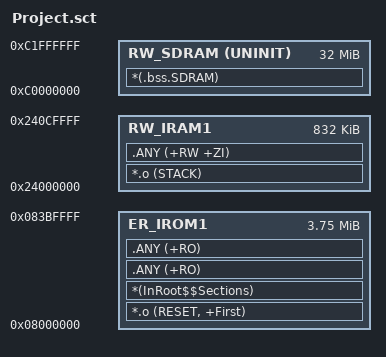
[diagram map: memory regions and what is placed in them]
; *************************************************************
; *** Scatter-Loading Description File generated by uVision ***
; *************************************************************

LR_IROM1 0x08000000 0x003C0000  {    ; load region size_region
  ER_IROM1 0x08000000 0x003C0000  {  ; load address = execution address
   *.o (RESET, +First)
   *(InRoot$$Sections)
   .ANY (+RO)
  .ANY (+RO)
  }
  RW_IRAM1 0x24000000 0x000D0000  {  ; RW data
    *.o (STACK)
   .ANY (+RW +ZI)
  }
  ; ITCM (0x00000000, 64KB) is left unused: the IPA/DMA can't access it.

  ; SDRAM 32MB, usable only after exmc_synchronous_dynamic_ram_init().
  ; UNINIT + ZI sections only (`__attribute__((section(".bss.SDRAM")))`), so the
  ; startup code never touches it. HEAP stays in RW_IRAM1 (.ANY) for the same reason.
  RW_SDRAM 0xC0000000 UNINIT 0x2000000  {
    *(.bss.SDRAM)
  }
}

